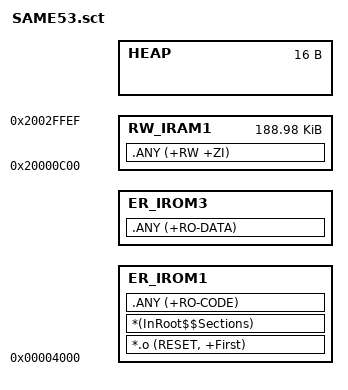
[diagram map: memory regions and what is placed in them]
#! armcc -E

; *************************************************************
; *** Scatter-Loading Description File generated by uVision ***
; *************************************************************

#define __RO_DATA_BASE 0x00020000

LR_IROM1 0x00004000 0x0007C000
{
    ER_IROM1 +0                   
    {
        *.o (RESET, +First)
        *(InRoot$$Sections)
        .ANY (+RO-CODE)
    }

;    ER_IROM2 +0 FILL 0xFFFFFFFF (__RO_DATA_BASE-ImageLimit(ER_IROM1))
;    {
;    }

    ER_IROM3 +0 ;__RO_DATA_BASE
    { 
        .ANY (+RO-DATA)
    }

    RW_IRAM1 0x20000C00 0x00002F3F0     ; RW data
    {  
        .ANY (+RW +ZI)
    }

    HEAP +0 FILL 0x55555555 0x10
    {
    }

}

